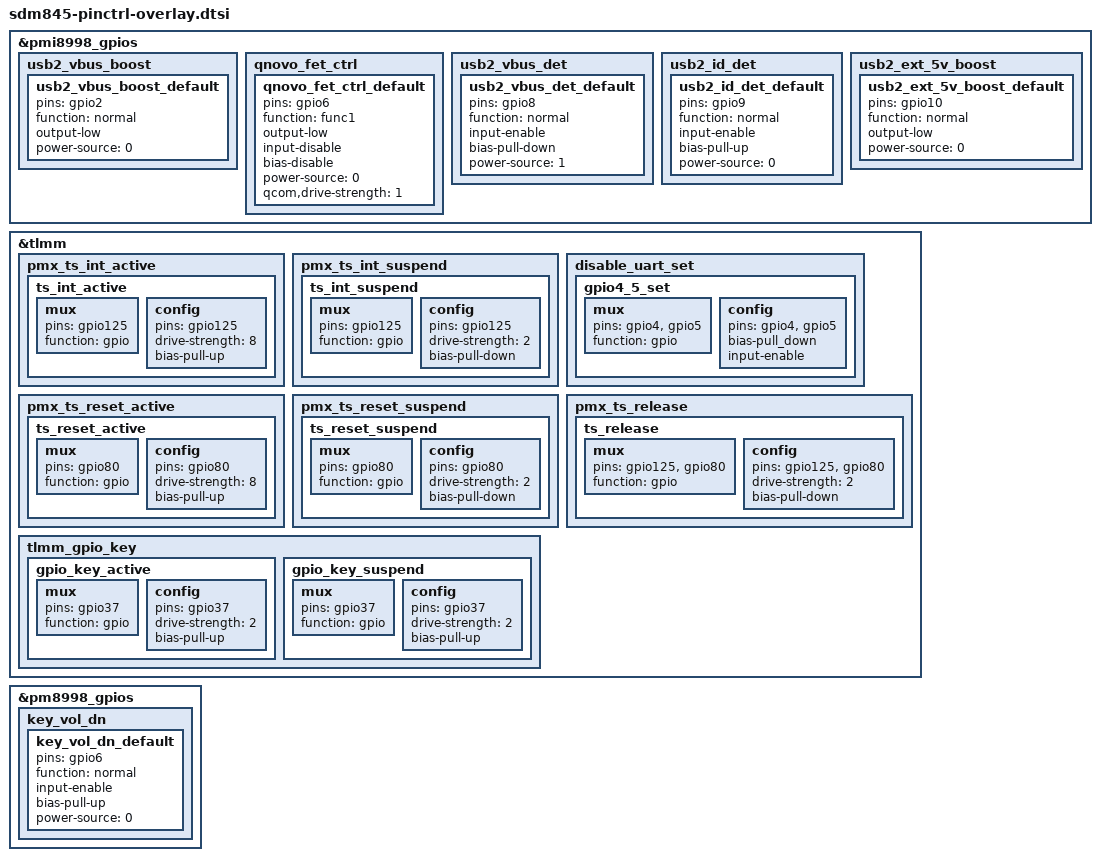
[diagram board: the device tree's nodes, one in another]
/* Copyright (c) 2017, The Linux Foundation. All rights reserved.
 *
 * This program is free software; you can redistribute it and/or modify
 * it under the terms of the GNU General Public License version 2 and
 * only version 2 as published by the Free Software Foundation.
 *
 * This program is distributed in the hope that it will be useful,
 * but WITHOUT ANY WARRANTY; without even the implied warranty of
 * MERCHANTABILITY or FITNESS FOR A PARTICULAR PURPOSE.  See the
 * GNU General Public License for more details.
 */

&pmi8998_gpios {
	usb2_vbus_boost {
		usb2_vbus_boost_default: usb2_vbus_boost_default {
			pins = "gpio2";
			function = "normal";
			output-low;
			power-source = <0>;
		};
	};

	qnovo_fet_ctrl {
		qnovo_fet_ctrl_default: qnovo_fet_ctrl_default {
			pins = "gpio6";
			function = "func1";
			output-low;
			input-disable;
			bias-disable;
			power-source = <0>;
			qcom,drive-strength = <1>;
		};
	};

	usb2_vbus_det {
		usb2_vbus_det_default: usb2_vbus_det_default {
			pins = "gpio8";
			function = "normal";
			input-enable;
			bias-pull-down;
			power-source = <1>;	/* VPH input supply */
		};
	};

	usb2_id_det {
		usb2_id_det_default: usb2_id_det_default {
			pins = "gpio9";
			function = "normal";
			input-enable;
			bias-pull-up;
			power-source = <0>;
		};
	};

	usb2_ext_5v_boost {
		usb2_ext_5v_boost_default: usb2_ext_5v_boost_default {
			pins = "gpio10";
			function = "normal";
			output-low;
			power-source = <0>;
		};
	};
};

&tlmm {
	pmx_ts_int_active {
		ts_int_active: ts_int_active {
			mux {
				pins = "gpio125";
				function = "gpio";
			};

			config {
				pins = "gpio125";
				drive-strength = <8>;
				bias-pull-up;
			};
		};
	};

	pmx_ts_int_suspend {
		ts_int_suspend: ts_int_suspend {
			mux {
				pins = "gpio125";
				function = "gpio";
			};

			config {
				pins = "gpio125";
				drive-strength = <2>;
				bias-pull-down;
			};
		};
	};
	disable_uart_set {
		gpio4_5_set: gpio4_5_set {
			mux {
				pins = "gpio4","gpio5";
				function = "gpio";
			};
			config {
				pins ="gpio4","gpio5";
				bias-pull_down;
				input-enable;
			};
		};
	};
	pmx_ts_reset_active {
		ts_reset_active: ts_reset_active {
			mux {
				pins = "gpio80";
				function = "gpio";
			};

			config {
				pins = "gpio80";
				drive-strength = <8>;
				bias-pull-up;
			};
		};
	};

	pmx_ts_reset_suspend {
		ts_reset_suspend: ts_reset_suspend {
			mux {
				pins = "gpio80";
				function = "gpio";
			};

			config {
				pins = "gpio80";
				drive-strength = <2>;
				bias-pull-down;
			};
		};
	};

	pmx_ts_release {
		ts_release: ts_release {
			mux {
				pins = "gpio125", "gpio80";
				function = "gpio";
			};

			config {
				pins = "gpio125", "gpio80";
				drive-strength = <2>;
				bias-pull-down;
			};
		};
	};

	tlmm_gpio_key {
		gpio_key_active: gpio_key_active {
			mux {
				pins = "gpio37";
				function = "gpio";
			};

			config {
				pins = "gpio37";
				drive-strength = <2>;
				bias-pull-up;
			};
		};

		gpio_key_suspend: gpio_key_suspend {
			mux {
				pins = "gpio37";
				function = "gpio";
			};

			config {
				pins = "gpio37";
				drive-strength = <2>;
				bias-pull-up;
			};
		};
	};
};

&pm8998_gpios {
	key_vol_dn {
		key_vol_dn_default: key_vol_dn_default {
			pins = "gpio6";
			function = "normal";
			input-enable;
			bias-pull-up;
			power-source = <0>;
		};
	};
};
